# YTM32B1ME0 register map
Vendor: YTMicro; File version: 1.2
CPU: CM33 r0p4, little endian, MPU, FPU, 2 interrupt priority bits
Registers are 32-bit, read-write, reset 0x0 unless marked. A register's access mark holds for its fields unless they carry their own. Offsets are from the block's base; [hi:lo] are bit positions.

## lpTMR0 — Low Power Timer
Base 0x4005D000; register names take the prefix lpTMR0_
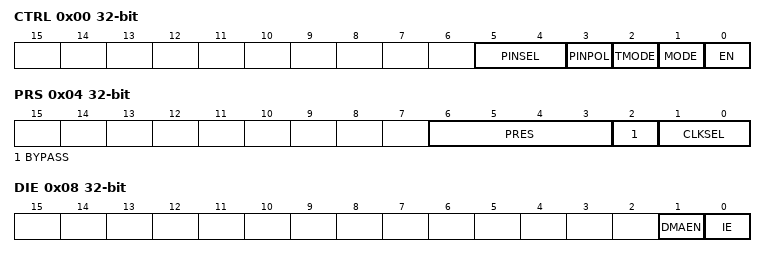
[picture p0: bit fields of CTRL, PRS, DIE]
0x00 CTRL
  [5:4] PINSEL — Configures the input source to be used in Pulse Counter mode. PINSEL must be altered only when the lpTMR is disabled.
    0=Pulse counter input 0 is selected. (It's from TMU); 1=Pulse counter input 1 is selected. (It's from lpTMR_ALT1 pad); 2=Pulse counter input 2 is selected. (It's from lpTMR_ALT2 pad); 3=Pulse counter input 3 is selected. (It's from lpTMR_ALT3 pad)
  [3] PINPOL — Configures the polarity of the input source in Pulse Counter mode. PINPOL must be changed only when the lpTMR is disabled.
    0=Pulse Counter input source is active-high, and the CNT will increment on the rising-edge; 1=Pulse Counter input source is active-low, and the CNT will increment on the falling-edge
  [2] TMODE — When clear, TMODE configures the CNT to reset whenever CCF is set. When set, TMODE configures the CNT to reset on overflow. TMODE must be altered only when the lpTMR is disabled.
    0=CNT is reset whenever CCF is set; 1=CNT is reset on overflow
  [1] MODE — Configures the mode of the lpTMR. MODE must be altered only when the lpTMR is disabled.
    0=Time Counter mode; 1=Pulse Counter mode
  [0] EN — When EN is clear, it resets the lpTMR internal logic, including the CNT and CCF. When EN is set, the lpTMR is enabled. While writing 1 to this field, CTRL[5:1] must not be altered.
    0=lpTMR is disabled and internal logic is reset; 1=lpTMR is enabled
0x04 PRS
  [6:3] PRES — Configures the size of the Prescaler in Time Counter mode or width of the glitch filter in Pulse Counter mode. The width of the glitch filter can vary by 1 cycle due to synchronization of the pulse counter input. PRESCALE must be altered only when the lpTMR is disabled.
    0=Prescaler divides the prescaler clock by 2; glitch filter does not support this configuration; 1=Prescaler divides the prescaler clock by 4; glitch filter recognizes change on input pin after 2 rising clock edges; 2=Prescaler divides the prescaler clock by 8; glitch filter recognizes change on input pin after 4 rising clock edges; 3=Prescaler divides the prescaler clock by 16; glitch filter recognizes change on input pin after 8 rising clock edges; 4=Prescaler divides the prescaler clock by 32; glitch filter recognizes change on input pin after 16 rising clock edges; 5=Prescaler divides the prescaler clock by 64; glitch filter recognizes change on input pin after 32 rising clock edges; 6=Prescaler divides the prescaler clock by 128; glitch filter recognizes change on input pin after 64 rising clock edges; 7=Prescaler divides the prescaler clock by 256; glitch filter recognizes change on input pin after 128 rising clock edges; 8=Prescaler divides the prescaler clock by 512; glitch filter recognizes change on input pin after 256 rising clock edges; 9=Prescaler divides the prescaler clock by 1024; glitch filter recognizes change on input pin after 512 rising clock edges; 10=Prescaler divides the prescaler clock by 2048; glitch filter recognizes change on input pin after 1024 rising clock edges; 11=Prescaler divides the prescaler clock by 4096; glitch filter recognizes change on input pin after 2048 rising clock edges; 12=Prescaler divides the prescaler clock by 8192; glitch filter recognizes change on input pin after 4096 rising clock edges; 13=Prescaler divides the prescaler clock by 16384; glitch filter recognizes change on input pin after 8192 rising clock edges; 14=Prescaler divides the prescaler clock by 32768; glitch filter recognizes change on input pin after 16384 rising clock edges; 15=Prescaler divides the prescaler clock by 65536; glitch filter recognizes change on input pin after 32768 rising clock edges
  [2] BYPASS — When BYPASS is set, the selected prescaler clock in Time Counter mode or selected input source in Pulse Counter mode directly clocks the CNT. When BYPASS is clear, the CNT is clocked by the output of the prescaler/glitch filter. BYPASS must be altered only when the lpTMR is disabled.
  [1:0] CLKSEL
    0=func_clk (cannot be used in Powerdown mode); 1=SIRC; 2=SXOSC
0x08 DIE
  [1] DMAEN — When TDRE is set, the lpTMR DMA Request is generated whenever CCF is also set and the CCF is cleared when the DMA Controller is done.
    0=Timer DMA Request disabled; 1=Timer DMA Request enabled
  [0] IE — When IE is set, the lpTMR Interrupt is generated whenever CCF is also set.
    0=Timer interrupt disabled; 1=Timer interrupt enabled
0x0C STS
  [0] CCF — CCF is set when the lpTMR is enabled and the CNT equals the CMP and increments. CCF is cleared when the lpTMR is disabled or writing 1 to it.
    0=The value of CNT is not equal to CMP and increments; 1=The value of CNT is equal to CMP and increments
0x10 CMP
  [15:0] CMP — When the lpTMR is enabled and the CNT equals the value in the CMP and increments, CCF is set and the hardware trigger asserts until the next time the CNT increments. If the CMP is 0, the hardware trigger will remain asserted until the lpTMR is disabled. If the lpTMR is enabled, the CMP must be altered only when CCF is set.
0x14 LCNT wo
  [15:0] LCVAL — Write this register to latch timer counter value to CNT register, which is to avoid metastability.
0x18 CNT
  [15:0] CVAL — The CNT returns the current value of the lpTMR counter at the time this LCNT register was last written.
